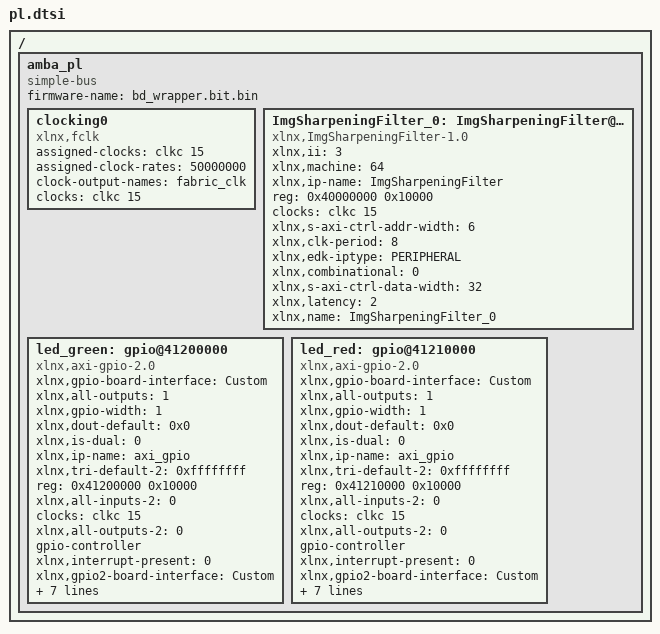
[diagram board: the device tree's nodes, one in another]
/ {
	amba_pl: amba_pl {
		ranges;
		compatible = "simple-bus";
		#address-cells = <1>;
		#size-cells = <1>;
		firmware-name = "bd_wrapper.bit.bin";
		clocking0: clocking0 {
			compatible = "xlnx,fclk";
			assigned-clocks = <&clkc 15>;
			assigned-clock-rates = <50000000>;
			#clock-cells = <0>;
			clock-output-names = "fabric_clk";
			clocks = <&clkc 15>;
		};
		ImgSharpeningFilter_0: ImgSharpeningFilter@40000000 {
			compatible = "xlnx,ImgSharpeningFilter-1.0";
			xlnx,ii = <3>;
			xlnx,machine = <64>;
			xlnx,ip-name = "ImgSharpeningFilter";
			reg = <0x40000000 0x10000>;
			clocks = <&clkc 15>;
			xlnx,s-axi-ctrl-addr-width = <6>;
			xlnx,clk-period = <8>;
			xlnx,edk-iptype = "PERIPHERAL";
			status = "okay";
			clock-names = "ap_clk";
			xlnx,combinational = <0>;
			xlnx,s-axi-ctrl-data-width = <32>;
			xlnx,latency = <2>;
			xlnx,name = "ImgSharpeningFilter_0";
		};
		led_green: gpio@41200000 {
			xlnx,gpio-board-interface = "Custom";
			compatible = "xlnx,axi-gpio-2.0" , "xlnx,xps-gpio-1.00.a";
			xlnx,all-outputs = <1>;
			#gpio-cells = <2>;
			xlnx,gpio-width = <1>;
			xlnx,dout-default = <0x0>;
			xlnx,is-dual = <0>;
			xlnx,ip-name = "axi_gpio";
			xlnx,tri-default-2 = <0xffffffff>;
			reg = <0x41200000 0x10000>;
			xlnx,all-inputs-2 = <0>;
			clocks = <&clkc 15>;
			xlnx,all-outputs-2 = <0>;
			gpio-controller;
			xlnx,interrupt-present = <0>;
			xlnx,gpio2-board-interface = "Custom";
			xlnx,edk-iptype = "PERIPHERAL";
			xlnx,dout-default-2 = <0x0>;
			status = "okay";
			xlnx,gpio2-width = <32>;
			clock-names = "s_axi_aclk";
			xlnx,use-board-flow;
			xlnx,tri-default = <0xffffffff>;
			xlnx,name = "led_green";
			xlnx,all-inputs = <0>;
		};
		led_red: gpio@41210000 {
			xlnx,gpio-board-interface = "Custom";
			compatible = "xlnx,axi-gpio-2.0" , "xlnx,xps-gpio-1.00.a";
			xlnx,all-outputs = <1>;
			#gpio-cells = <2>;
			xlnx,gpio-width = <1>;
			xlnx,dout-default = <0x0>;
			xlnx,is-dual = <0>;
			xlnx,ip-name = "axi_gpio";
			xlnx,tri-default-2 = <0xffffffff>;
			reg = <0x41210000 0x10000>;
			xlnx,all-inputs-2 = <0>;
			clocks = <&clkc 15>;
			xlnx,all-outputs-2 = <0>;
			gpio-controller;
			xlnx,interrupt-present = <0>;
			xlnx,gpio2-board-interface = "Custom";
			xlnx,edk-iptype = "PERIPHERAL";
			xlnx,dout-default-2 = <0x0>;
			status = "okay";
			xlnx,gpio2-width = <32>;
			clock-names = "s_axi_aclk";
			xlnx,use-board-flow;
			xlnx,tri-default = <0xffffffff>;
			xlnx,name = "led_red";
			xlnx,all-inputs = <0>;
		};
	};
};
